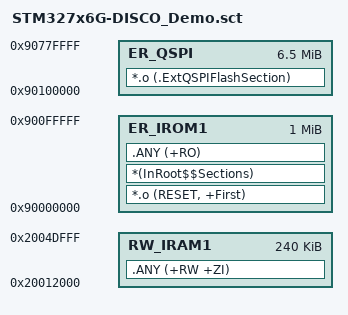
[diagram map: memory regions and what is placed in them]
; *************************************************************
; *** Scatter-Loading Description File generated by uVision ***
; *************************************************************

LR_IROM1 0x90000000 0x0100000  {    ; load region size_region
  ER_IROM1 0x90000000 0x0100000  {  ; load address = execution address
   *.o (RESET, +First)
   *(InRoot$$Sections)
   .ANY (+RO)
  }
  RW_IRAM1 0x20012000 0x0003C000  {  ; RW data
   .ANY (+RW +ZI)
  }
}

   LR_QSPI 0x90100000 0x680000  {
   ER_QSPI 0x90100000 0x680000 {
	*.o (.ExtQSPIFlashSection)          
  }
}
